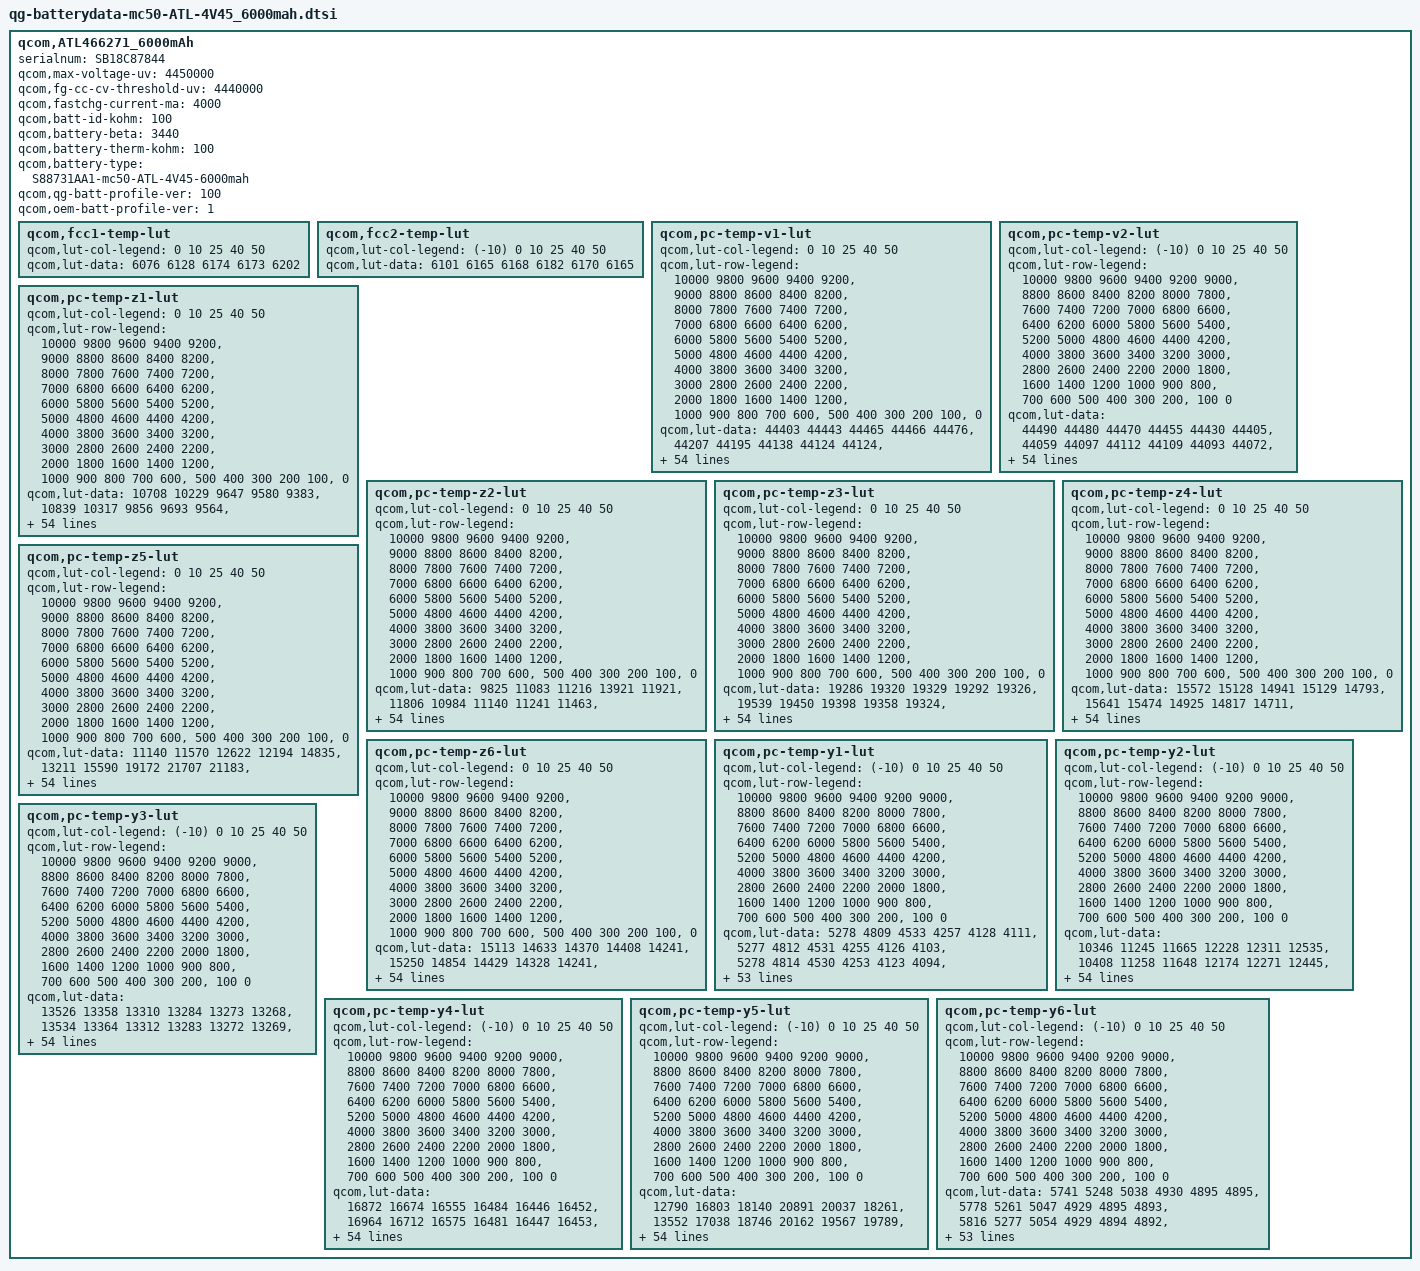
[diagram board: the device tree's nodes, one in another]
qcom,ATL466271_6000mAh {
	/* ATL466271_6000mAh_averaged_MasterSlave_Aug7th2020 */
        serialnum = "SB18C87844";
	qcom,max-voltage-uv = <4450000>;
	qcom,fg-cc-cv-threshold-uv = <4440000>;
	qcom,fastchg-current-ma = <4000>;
	qcom,batt-id-kohm = <100>;
	qcom,battery-beta = <3440>;
	qcom,battery-therm-kohm = <100>; /* on sub-board 100K */
	qcom,battery-type = "S88731AA1-mc50-ATL-4V45-6000mah";
	qcom,qg-batt-profile-ver = <100>;
        qcom,oem-batt-profile-ver = <1>;

	/*qcom,step-chg-ranges = <3500000  4000000  8000000
				4000001  4200000  6000000
				4200001  4400000  4000000>;
	qcom,ocv-based-step-chg;*/

	qcom,fcc1-temp-lut {
		qcom,lut-col-legend = <0 10 25 40 50>;
		qcom,lut-data = <6076 6128 6174 6173 6202>;
	};

	qcom,fcc2-temp-lut {
		qcom,lut-col-legend = <(-10) 0 10 25 40 50>;
		qcom,lut-data = <6101 6165 6168 6182 6170 6165>;
	};

	qcom,pc-temp-v1-lut {
		qcom,lut-col-legend = <0 10 25 40 50>;
		qcom,lut-row-legend = <10000 9800 9600 9400 9200>,
			<9000 8800 8600 8400 8200>,
			<8000 7800 7600 7400 7200>,
			<7000 6800 6600 6400 6200>,
			<6000 5800 5600 5400 5200>,
			<5000 4800 4600 4400 4200>,
			<4000 3800 3600 3400 3200>,
			<3000 2800 2600 2400 2200>,
			<2000 1800 1600 1400 1200>,
			<1000 900 800 700 600>,
			<500 400 300 200 100>,
			<0>;
		qcom,lut-data = <44403 44443 44465 44466 44476>,
			<44207 44195 44138 44124 44124>,
			<43961 43947 43889 43906 43859>,
			<43706 43716 43668 43683 43637>,
			<43464 43481 43444 43456 43420>,
			<43222 43244 43209 43224 43190>,
			<42977 43004 42970 42987 42956>,
			<42728 42756 42726 42745 42718>,
			<42478 42504 42477 42497 42476>,
			<42231 42258 42230 42251 42234>,
			<41986 42014 41986 42008 41993>,
			<41748 41775 41746 41768 41754>,
			<41517 41542 41511 41532 41520>,
			<41292 41313 41279 41298 41288>,
			<41075 41095 41056 41072 41064>,
			<40864 40885 40840 40852 40846>,
			<40655 40679 40633 40643 40636>,
			<40445 40472 40434 40449 40434>,
			<40250 40276 40245 40265 40242>,
			<40073 40105 40072 40089 40061>,
			<39907 39948 39915 39926 39897>,
			<39750 39775 39731 39740 39718>,
			<39603 39585 39458 39491 39482>,
			<39439 39381 39186 39240 39233>,
			<39226 39134 39019 39062 39050>,
			<39010 38883 38898 38918 38905>,
			<38843 38750 38789 38789 38778>,
			<38699 38679 38689 38670 38664>,
			<38599 38617 38596 38563 38560>,
			<38535 38547 38506 38471 38459>,
			<38485 38481 38422 38389 38363>,
			<38437 38415 38349 38315 38278>,
			<38394 38353 38284 38248 38202>,
			<38353 38296 38226 38185 38133>,
			<38312 38247 38179 38127 38075>,
			<38273 38202 38136 38073 38021>,
			<38238 38162 38091 38019 37960>,
			<38204 38127 38048 37968 37896>,
			<38155 38079 37993 37905 37822>,
			<38077 37995 37911 37816 37735>,
			<37976 37889 37808 37714 37633>,
			<37859 37774 37693 37618 37515>,
			<37716 37637 37559 37514 37378>,
			<37541 37469 37397 37353 37246>,
			<37374 37294 37232 37162 37115>,
			<37241 37166 37111 37043 36978>,
			<37204 37126 37082 37018 36967>,
			<37166 37098 37059 36985 36935>,
			<37132 37079 37040 36970 36911>,
			<37097 37047 37009 36938 36866>,
			<36970 36897 36822 36732 36622>,
			<36569 36486 36406 36316 36186>,
			<35983 35903 35832 35755 35657>,
			<35173 35096 35048 35001 34835>,
			<33799 33762 33835 33744 33618>,
			<30000 30000 30000 30000 30000>;
	};

	qcom,pc-temp-v2-lut {
		qcom,lut-col-legend = <(-10) 0 10 25 40 50>;
		qcom,lut-row-legend = <10000 9800 9600 9400 9200 9000>,
			<8800 8600 8400 8200 8000 7800>,
			<7600 7400 7200 7000 6800 6600>,
			<6400 6200 6000 5800 5600 5400>,
			<5200 5000 4800 4600 4400 4200>,
			<4000 3800 3600 3400 3200 3000>,
			<2800 2600 2400 2200 2000 1800>,
			<1600 1400 1200 1000 900 800>,
			<700 600 500 400 300 200>,
			<100 0>;
		qcom,lut-data = <44490 44480 44470 44455 44430 44405>,
			<44059 44097 44112 44109 44093 44072>,
			<43685 43762 43798 43802 43792 43771>,
			<43382 43487 43534 43541 43534 43512>,
			<43138 43260 43315 43321 43315 43289>,
			<42893 43030 43091 43097 43092 43062>,
			<42622 42783 42849 42856 42854 42818>,
			<42352 42532 42602 42612 42612 42571>,
			<42104 42278 42355 42367 42369 42327>,
			<41872 42022 42107 42121 42124 42083>,
			<41639 41777 41864 41877 41883 41843>,
			<41395 41542 41624 41636 41644 41605>,
			<41159 41316 41389 41401 41410 41372>,
			<40955 41097 41159 41171 41183 41144>,
			<40771 40884 40935 40948 40963 40922>,
			<40541 40673 40720 40731 40750 40707>,
			<40203 40468 40513 40521 40543 40498>,
			<39855 40251 40312 40318 40342 40298>,
			<39587 40004 40125 40129 40149 40111>,
			<39354 39743 39938 39944 39957 39931>,
			<39127 39497 39712 39745 39758 39748>,
			<38902 39258 39441 39534 39551 39567>,
			<38703 39041 39197 39320 39342 39371>,
			<38534 38849 38995 39088 39115 39133>,
			<38388 38676 38817 38874 38902 38902>,
			<38286 38523 38665 38720 38749 38744>,
			<38215 38385 38533 38596 38625 38621>,
			<38154 38261 38413 38483 38512 38511>,
			<38098 38142 38302 38377 38401 38407>,
			<38047 38044 38200 38280 38303 38310>,
			<37993 37981 38105 38192 38224 38222>,
			<37938 37934 38018 38112 38154 38140>,
			<37883 37890 37944 38039 38082 38066>,
			<37827 37850 37878 37972 38002 38003>,
			<37771 37808 37824 37906 37927 37934>,
			<37711 37760 37784 37836 37863 37836>,
			<37647 37706 37748 37764 37798 37721>,
			<37578 37646 37701 37686 37718 37613>,
			<37505 37579 37639 37603 37620 37509>,
			<37425 37501 37566 37521 37520 37411>,
			<37337 37398 37474 37446 37424 37328>,
			<37237 37279 37363 37356 37318 37236>,
			<37122 37147 37225 37231 37191 37110>,
			<37003 36987 37075 37102 37067 36978>,
			<36901 36830 36901 36935 36903 36835>,
			<36812 36722 36816 36890 36860 36802>,
			<36769 36681 36780 36873 36851 36789>,
			<36728 36642 36750 36853 36870 36770>,
			<36686 36592 36694 36824 36818 36741>,
			<36634 36504 36602 36751 36729 36647>,
			<36528 36300 36369 36488 36455 36338>,
			<36286 35864 35889 36000 35960 35833>,
			<35817 35150 35212 35350 35298 35166>,
			<35058 34089 34305 34448 34424 34230>,
			<33775 32410 32840 33043 33144 32821>,
			<32320 28352 28072 28339 28428 29837>;
	};

	qcom,pc-temp-z1-lut {
		qcom,lut-col-legend = <0 10 25 40 50>;
		qcom,lut-row-legend = <10000 9800 9600 9400 9200>,
			<9000 8800 8600 8400 8200>,
			<8000 7800 7600 7400 7200>,
			<7000 6800 6600 6400 6200>,
			<6000 5800 5600 5400 5200>,
			<5000 4800 4600 4400 4200>,
			<4000 3800 3600 3400 3200>,
			<3000 2800 2600 2400 2200>,
			<2000 1800 1600 1400 1200>,
			<1000 900 800 700 600>,
			<500 400 300 200 100>,
			<0>;
		qcom,lut-data = <10708 10229 9647 9580 9383>,
			<10839 10317 9856 9693 9564>,
			<10850 10320 9850 9738 9541>,
			<10856 10326 9844 9730 9540>,
			<10864 10326 9838 9720 9539>,
			<10877 10320 9831 9703 9538>,
			<10875 10312 9824 9689 9537>,
			<10846 10300 9818 9691 9538>,
			<10821 10285 9812 9701 9545>,
			<10818 10276 9809 9702 9547>,
			<10819 10269 9806 9666 9541>,
			<10816 10264 9804 9635 9534>,
			<10805 10260 9802 9653 9538>,
			<10795 10257 9800 9691 9553>,
			<10789 10256 9799 9695 9557>,
			<10782 10256 9797 9662 9544>,
			<10776 10255 9796 9639 9534>,
			<10770 10248 9798 9638 9537>,
			<10766 10241 9801 9637 9544>,
			<10768 10246 9801 9638 9550>,
			<10770 10257 9799 9638 9557>,
			<10770 10262 9798 9639 9560>,
			<10767 10264 9799 9662 9552>,
			<10767 10265 9801 9687 9542>,
			<10775 10265 9803 9680 9542>,
			<10786 10265 9807 9656 9546>,
			<10784 10266 9811 9648 9548>,
			<10771 10272 9815 9654 9549>,
			<10766 10276 9819 9662 9549>,
			<10775 10275 9823 9669 9550>,
			<10787 10271 9826 9675 9552>,
			<10796 10271 9828 9678 9557>,
			<10804 10273 9830 9679 9575>,
			<10807 10276 9833 9681 9588>,
			<10806 10282 9836 9683 9583>,
			<10806 10291 9840 9684 9574>,
			<10819 10298 9843 9685 9575>,
			<10846 10306 9845 9686 9584>,
			<10854 10309 9847 9687 9589>,
			<10845 10307 9851 9693 9587>,
			<10837 10306 9855 9702 9584>,
			<10845 10320 9862 9709 9590>,
			<10865 10342 9870 9717 9604>,
			<10887 10342 9873 9742 9596>,
			<10908 10346 9878 9749 9583>,
			<10904 10348 9882 9737 9594>,
			<10898 10362 9884 9738 9586>,
			<10904 10366 9886 9730 9574>,
			<10906 10354 9882 9741 9575>,
			<10885 10364 9887 9738 9577>,
			<10915 10372 9895 9751 9580>,
			<10908 10384 9906 9765 9624>,
			<10963 10405 9909 9725 9601>,
			<11011 10440 9926 9751 9592>,
			<11011 10440 9926 9751 9592>,
			<11011 10440 9926 9751 9592>;
	};

	qcom,pc-temp-z2-lut {
		qcom,lut-col-legend = <0 10 25 40 50>;
		qcom,lut-row-legend = <10000 9800 9600 9400 9200>,
			<9000 8800 8600 8400 8200>,
			<8000 7800 7600 7400 7200>,
			<7000 6800 6600 6400 6200>,
			<6000 5800 5600 5400 5200>,
			<5000 4800 4600 4400 4200>,
			<4000 3800 3600 3400 3200>,
			<3000 2800 2600 2400 2200>,
			<2000 1800 1600 1400 1200>,
			<1000 900 800 700 600>,
			<500 400 300 200 100>,
			<0>;
		qcom,lut-data = <9825 11083 11216 13921 11921>,
			<11806 10984 11140 11241 11463>,
			<11214 10949 11207 11503 11629>,
			<10684 10840 11132 11435 11585>,
			<10624 10788 11066 11386 11550>,
			<10596 10733 11020 11374 11574>,
			<10590 10683 10988 11374 11614>,
			<10593 10644 11001 11389 11610>,
			<10593 10614 11045 11419 11554>,
			<10574 10622 11077 11426 11506>,
			<10542 10673 11099 11379 11497>,
			<10536 10713 11118 11337 11508>,
			<10540 10729 11135 11360 11513>,
			<10548 10743 11150 11414 11501>,
			<10573 10767 11170 11438 11491>,
			<10607 10799 11198 11464 11498>,
			<10618 10827 11223 11478 11507>,
			<10620 10851 11241 11453 11522>,
			<10624 10873 11256 11415 11547>,
			<10643 10896 11273 11406 11552>,
			<10673 10921 11294 11407 11569>,
			<10697 10941 11321 11430 11618>,
			<10721 10961 11385 11480 11931>,
			<10739 10973 11446 11539 12346>,
			<10751 10974 11411 11632 12383>,
			<10760 10973 11287 11775 12253>,
			<10771 10972 11246 11814 12119>,
			<10783 10968 11351 11700 11878>,
			<10795 10967 11449 11561 11649>,
			<10809 10983 11416 11460 11588>,
			<10823 11006 11334 11358 11552>,
			<10835 11013 11295 11338 11536>,
			<10846 11014 11273 11359 11529>,
			<10856 11015 11263 11392 11536>,
			<10863 11018 11293 11465 11557>,
			<10870 11022 11349 11556 11588>,
			<10878 11026 11383 11589 11656>,
			<10887 11030 11408 11595 11821>,
			<10900 11039 11432 11597 11911>,
			<10919 11066 11466 11598 11903>,
			<10943 11095 11496 11599 11894>,
			<10966 11106 11501 11684 11935>,
			<10997 11115 11496 11868 12059>,
			<11062 11134 11499 11881 11996>,
			<11187 11262 11550 11776 12022>,
			<11338 11556 11646 11627 12000>,
			<11040 11551 11653 11644 12454>,
			<10950 11673 11585 11576 12004>,
			<10958 12095 11610 11558 11921>,
			<10509 12218 11649 11614 12049>,
			<10765 12168 11877 11644 11613>,
			<10420 12160 12029 11864 11419>,
			<10349 11922 11952 13651 11585>,
			<10177 11499 11848 13870 11361>,
			<10177 11499 11848 13870 11361>,
			<10177 11499 11848 13870 11361>;
	};

	qcom,pc-temp-z3-lut {
		qcom,lut-col-legend = <0 10 25 40 50>;
		qcom,lut-row-legend = <10000 9800 9600 9400 9200>,
			<9000 8800 8600 8400 8200>,
			<8000 7800 7600 7400 7200>,
			<7000 6800 6600 6400 6200>,
			<6000 5800 5600 5400 5200>,
			<5000 4800 4600 4400 4200>,
			<4000 3800 3600 3400 3200>,
			<3000 2800 2600 2400 2200>,
			<2000 1800 1600 1400 1200>,
			<1000 900 800 700 600>,
			<500 400 300 200 100>,
			<0>;
		qcom,lut-data = <19286 19320 19329 19292 19326>,
			<19539 19450 19398 19358 19324>,
			<19620 19495 19432 19353 19349>,
			<19669 19551 19443 19360 19350>,
			<19703 19570 19447 19363 19350>,
			<19727 19577 19445 19361 19349>,
			<19730 19580 19440 19357 19347>,
			<19721 19582 19434 19358 19346>,
			<19713 19582 19424 19361 19345>,
			<19715 19576 19415 19361 19343>,
			<19719 19555 19408 19355 19336>,
			<19719 19539 19402 19350 19327>,
			<19714 19531 19399 19351 19327>,
			<19706 19525 19397 19355 19327>,
			<19696 19518 19394 19355 19327>,
			<19685 19510 19391 19350 19320>,
			<19680 19506 19389 19343 19315>,
			<19677 19501 19386 19335 19316>,
			<19673 19498 19384 19326 19317>,
			<19660 19496 19381 19324 19317>,
			<19645 19492 19377 19324 19314>,
			<19640 19492 19375 19324 19313>,
			<19638 19496 19387 19340 19318>,
			<19639 19500 19401 19356 19327>,
			<19649 19503 19395 19352 19328>,
			<19660 19507 19373 19336 19322>,
			<19660 19506 19366 19332 19319>,
			<19656 19496 19373 19355 19325>,
			<19652 19489 19382 19376 19333>,
			<19646 19490 19392 19373 19333>,
			<19639 19490 19404 19364 19332>,
			<19634 19492 19406 19358 19332>,
			<19628 19496 19402 19353 19331>,
			<19625 19498 19397 19349 19330>,
			<19622 19497 19392 19346 19324>,
			<19620 19495 19387 19345 19316>,
			<19617 19493 19384 19343 19315>,
			<19612 19489 19382 19342 19316>,
			<19608 19486 19380 19341 19317>,
			<19602 19481 19378 19340 19317>,
			<19596 19477 19376 19339 19317>,
			<19585 19472 19374 19332 19319>,
			<19571 19467 19373 19317 19323>,
			<19556 19458 19369 19314 19313>,
			<19477 19437 19361 19318 19297>,
			<19377 19401 19351 19318 19302>,
			<19308 19398 19347 19318 19290>,
			<19302 19382 19347 19320 19295>,
			<19295 19302 19342 19314 19295>,
			<19280 19289 19335 19311 19297>,
			<19288 19322 19325 19310 19308>,
			<19278 19296 19307 19301 19324>,
			<19299 19300 19309 19292 19299>,
			<19312 19305 19315 19293 19310>,
			<19312 19305 19315 19293 19310>,
			<19312 19305 19315 19293 19310>;
	};

	qcom,pc-temp-z4-lut {
		qcom,lut-col-legend = <0 10 25 40 50>;
		qcom,lut-row-legend = <10000 9800 9600 9400 9200>,
			<9000 8800 8600 8400 8200>,
			<8000 7800 7600 7400 7200>,
			<7000 6800 6600 6400 6200>,
			<6000 5800 5600 5400 5200>,
			<5000 4800 4600 4400 4200>,
			<4000 3800 3600 3400 3200>,
			<3000 2800 2600 2400 2200>,
			<2000 1800 1600 1400 1200>,
			<1000 900 800 700 600>,
			<500 400 300 200 100>,
			<0>;
		qcom,lut-data = <15572 15128 14941 15129 14793>,
			<15641 15474 14925 14817 14711>,
			<15716 15422 15016 14923 14752>,
			<15762 15236 14915 14870 14721>,
			<15654 15105 14830 14818 14692>,
			<15437 15005 14783 14777 14684>,
			<15285 14928 14750 14744 14680>,
			<15182 14872 14735 14733 14678>,
			<15098 14828 14725 14727 14679>,
			<15028 14795 14718 14719 14678>,
			<14968 14769 14713 14702 14673>,
			<14917 14753 14708 14689 14667>,
			<14874 14744 14702 14690 14666>,
			<14837 14739 14695 14694 14665>,
			<14802 14733 14689 14691 14663>,
			<14774 14727 14684 14671 14657>,
			<14764 14723 14680 14658 14649>,
			<14759 14723 14676 14659 14644>,
			<14757 14722 14672 14659 14639>,
			<14758 14715 14669 14658 14637>,
			<14760 14702 14667 14655 14637>,
			<14756 14698 14667 14655 14639>,
			<14739 14705 14699 14685 14658>,
			<14730 14718 14744 14723 14686>,
			<14748 14755 14765 14734 14698>,
			<14778 14809 14780 14741 14705>,
			<14800 14819 14783 14740 14707>,
			<14821 14808 14765 14708 14689>,
			<14828 14793 14742 14677 14666>,
			<14821 14779 14721 14674 14657>,
			<14809 14764 14700 14673 14650>,
			<14798 14751 14692 14672 14648>,
			<14787 14738 14689 14669 14649>,
			<14776 14730 14688 14668 14650>,
			<14766 14725 14687 14667 14650>,
			<14756 14721 14686 14668 14649>,
			<14747 14717 14686 14669 14651>,
			<14737 14713 14687 14673 14663>,
			<14730 14711 14688 14677 14669>,
			<14723 14711 14690 14682 14665>,
			<14718 14711 14693 14688 14660>,
			<14713 14705 14689 14689 14661>,
			<14708 14691 14677 14689 14664>,
			<14697 14684 14671 14694 14662>,
			<14719 14672 14661 14687 14653>,
			<14772 14664 14648 14666 14647>,
			<14844 14663 14644 14659 14644>,
			<14848 14672 14635 14648 14627>,
			<14851 14758 14630 14646 14616>,
			<14860 14765 14633 14643 14613>,
			<14847 14731 14656 14663 14617>,
			<14870 14768 14681 14679 14633>,
			<14860 14770 14679 14665 14624>,
			<14866 14773 14675 14657 14620>,
			<14866 14773 14675 14657 14620>,
			<14866 14773 14675 14657 14620>;
	};

	qcom,pc-temp-z5-lut {
		qcom,lut-col-legend = <0 10 25 40 50>;
		qcom,lut-row-legend = <10000 9800 9600 9400 9200>,
			<9000 8800 8600 8400 8200>,
			<8000 7800 7600 7400 7200>,
			<7000 6800 6600 6400 6200>,
			<6000 5800 5600 5400 5200>,
			<5000 4800 4600 4400 4200>,
			<4000 3800 3600 3400 3200>,
			<3000 2800 2600 2400 2200>,
			<2000 1800 1600 1400 1200>,
			<1000 900 800 700 600>,
			<500 400 300 200 100>,
			<0>;
		qcom,lut-data = <11140 11570 12622 12194 14835>,
			<13211 15590 19172 21707 21183>,
			<14425 15533 18678 17683 23043>,
			<15251 17215 20011 18761 24939>,
			<15887 18421 21410 19438 26507>,
			<16392 19285 22696 20026 27263>,
			<16864 20214 23721 20637 27776>,
			<17322 21489 24048 20903 27675>,
			<17834 22875 24179 21379 26644>,
			<18585 24056 24133 21600 25685>,
			<19619 25149 23973 21760 25147>,
			<20723 25958 23849 21848 24957>,
			<21930 26637 24196 22062 25339>,
			<23403 27127 25135 22588 25934>,
			<25620 27427 26019 23283 25948>,
			<28194 28023 26859 26556 25809>,
			<30330 28372 27768 28660 25909>,
			<32395 29691 28965 26570 28588>,
			<33283 30915 30263 23544 33478>,
			<31977 31327 31053 23193 34181>,
			<30157 32643 31717 23746 31511>,
			<30624 35054 33004 24740 30665>,
			<34427 42825 43943 29332 35941>,
			<39743 48777 56195 34073 42709>,
			<52852 49207 50724 31619 40441>,
			<65535 49140 31430 23448 26676>,
			<65535 47375 23864 20977 19864>,
			<61512 39006 23963 28594 21979>,
			<57109 33572 24595 35950 25007>,
			<52662 33637 27865 36181 27649>,
			<48821 33848 34423 34754 31558>,
			<46667 35005 38811 34530 34021>,
			<45097 39367 41938 35856 35705>,
			<44713 43466 43755 37643 36741>,
			<45530 46675 44421 41555 36954>,
			<46437 49082 44759 46148 36788>,
			<46768 49579 44614 46551 36128>,
			<47176 49175 44232 45155 34346>,
			<47879 48690 43559 43881 33460>,
			<50055 47864 40548 41648 36740>,
			<51749 46639 37429 38000 40549>,
			<48642 44975 37328 31529 38972>,
			<43305 42659 37677 23579 33171>,
			<43137 39303 35715 23720 25952>,
			<34797 37962 34411 28737 21728>,
			<21074 32012 35350 29274 23908>,
			<13843 29691 32903 28774 20866>,
			<13296 24496 34496 37721 26313>,
			<13048 14276 33055 33163 33103>,
			<12666 13340 28801 33205 34583>,
			<12947 15826 21358 24463 34247>,
			<12623 13660 16311 21348 35544>,
			<12872 13517 16200 20604 22641>,
			<12930 13512 16441 21168 28792>,
			<12930 13512 16441 21168 28792>,
			<12930 13512 16441 21168 28792>;
	};

	qcom,pc-temp-z6-lut {
		qcom,lut-col-legend = <0 10 25 40 50>;
		qcom,lut-row-legend = <10000 9800 9600 9400 9200>,
			<9000 8800 8600 8400 8200>,
			<8000 7800 7600 7400 7200>,
			<7000 6800 6600 6400 6200>,
			<6000 5800 5600 5400 5200>,
			<5000 4800 4600 4400 4200>,
			<4000 3800 3600 3400 3200>,
			<3000 2800 2600 2400 2200>,
			<2000 1800 1600 1400 1200>,
			<1000 900 800 700 600>,
			<500 400 300 200 100>,
			<0>;
		qcom,lut-data = <15113 14633 14370 14408 14241>,
			<15250 14854 14429 14328 14241>,
			<15291 14839 14481 14379 14267>,
			<15306 14781 14443 14359 14255>,
			<15264 14730 14408 14337 14243>,
			<15162 14680 14385 14313 14238>,
			<15080 14639 14367 14295 14235>,
			<15014 14610 14355 14292 14234>,
			<14960 14587 14345 14292 14235>,
			<14921 14562 14337 14289 14234>,
			<14890 14536 14330 14272 14227>,
			<14859 14519 14324 14257 14219>,
			<14829 14510 14319 14261 14218>,
			<14801 14504 14314 14272 14221>,
			<14777 14497 14310 14271 14220>,
			<14756 14490 14306 14254 14211>,
			<14747 14485 14303 14240 14203>,
			<14742 14482 14300 14235 14202>,
			<14738 14479 14297 14231 14201>,
			<14734 14474 14294 14229 14201>,
			<14731 14467 14291 14228 14201>,
			<14726 14466 14290 14228 14202>,
			<14716 14471 14313 14254 14212>,
			<14713 14480 14339 14284 14227>,
			<14728 14500 14341 14284 14231>,
			<14749 14526 14339 14275 14233>,
			<14761 14530 14337 14271 14233>,
			<14771 14522 14334 14270 14228>,
			<14773 14513 14330 14269 14223>,
			<14767 14506 14328 14267 14220>,
			<14758 14501 14325 14264 14217>,
			<14751 14498 14323 14261 14215>,
			<14746 14496 14320 14257 14219>,
			<14741 14494 14317 14254 14221>,
			<14737 14492 14315 14253 14216>,
			<14734 14490 14312 14252 14210>,
			<14732 14490 14311 14252 14210>,
			<14731 14489 14311 14253 14217>,
			<14730 14488 14311 14254 14221>,
			<14730 14489 14312 14257 14218>,
			<14729 14489 14313 14260 14215>,
			<14727 14487 14312 14258 14218>,
			<14724 14484 14307 14252 14224>,
			<14720 14481 14304 14258 14217>,
			<14701 14472 14297 14258 14203>,
			<14678 14454 14288 14246 14204>,
			<14678 14453 14284 14243 14195>,
			<14677 14450 14281 14238 14188>,
			<14676 14448 14276 14236 14183>,
			<14674 14447 14275 14233 14183>,
			<14681 14452 14282 14244 14191>,
			<14694 14460 14286 14250 14215>,
			<14711 14470 14288 14231 14194>,
			<14740 14484 14292 14234 14197>,
			<14740 14484 14292 14234 14197>,
			<14740 14484 14292 14234 14197>;
	};

	qcom,pc-temp-y1-lut {
		qcom,lut-col-legend = <(-10) 0 10 25 40 50>;
		qcom,lut-row-legend = <10000 9800 9600 9400 9200 9000>,
			<8800 8600 8400 8200 8000 7800>,
			<7600 7400 7200 7000 6800 6600>,
			<6400 6200 6000 5800 5600 5400>,
			<5200 5000 4800 4600 4400 4200>,
			<4000 3800 3600 3400 3200 3000>,
			<2800 2600 2400 2200 2000 1800>,
			<1600 1400 1200 1000 900 800>,
			<700 600 500 400 300 200>,
			<100 0>;
		qcom,lut-data = <5278 4809 4533 4257 4128 4111>,
			<5277 4812 4531 4255 4126 4103>,
			<5278 4814 4530 4253 4123 4094>,
			<5280 4815 4528 4250 4121 4085>,
			<5282 4815 4527 4248 4119 4077>,
			<5284 4816 4525 4245 4118 4072>,
			<5293 4815 4524 4241 4117 4070>,
			<5303 4814 4522 4238 4116 4068>,
			<5303 4817 4522 4237 4116 4067>,
			<5299 4826 4523 4237 4115 4064>,
			<5297 4829 4523 4237 4114 4064>,
			<5308 4821 4526 4234 4112 4065>,
			<5321 4815 4527 4231 4110 4065>,
			<5319 4817 4521 4231 4113 4065>,
			<5309 4822 4508 4230 4123 4064>,
			<5305 4823 4506 4229 4142 4064>,
			<5306 4822 4511 4227 4187 4063>,
			<5307 4820 4514 4226 4216 4063>,
			<5308 4820 4512 4226 4194 4064>,
			<5308 4819 4508 4227 4161 4066>,
			<5308 4819 4509 4229 4156 4066>,
			<5307 4819 4517 4231 4156 4066>,
			<5306 4820 4522 4232 4156 4066>,
			<5308 4822 4524 4232 4163 4067>,
			<5311 4824 4525 4232 4171 4069>,
			<5316 4828 4524 4232 4166 4069>,
			<5332 4833 4521 4232 4148 4069>,
			<5342 4837 4520 4233 4142 4069>,
			<5331 4842 4522 4236 4153 4070>,
			<5311 4845 4525 4240 4163 4070>,
			<5306 4847 4529 4242 4164 4071>,
			<5306 4852 4535 4245 4164 4072>,
			<5306 4853 4537 4247 4164 4073>,
			<5314 4849 4535 4249 4159 4074>,
			<5325 4846 4533 4251 4156 4075>,
			<5332 4846 4535 4254 4158 4076>,
			<5347 4847 4537 4257 4160 4078>,
			<5354 4850 4540 4258 4160 4078>,
			<5339 4859 4547 4259 4156 4079>,
			<5321 4865 4550 4260 4154 4079>,
			<5321 4861 4551 4265 4155 4080>,
			<5328 4857 4553 4267 4159 4081>,
			<5345 4855 4554 4269 4187 4082>,
			<5353 4867 4573 4272 4174 4082>,
			<5336 4860 4569 4272 4201 4082>,
			<5350 4872 4578 4278 4199 4084>,
			<5351 4871 4581 4280 4186 4085>,
			<5347 4877 4578 4278 4164 4085>,
			<5376 4889 4575 4280 4174 4086>,
			<5395 4890 4584 4284 4194 4086>,
			<5421 4896 4580 4283 4210 4086>,
			<5504 4940 4592 4288 4203 4089>,
			<5511 5014 4611 4300 4207 4092>,
			<5635 5122 4657 4314 4193 4094>,
			<5635 5122 4657 4314 4193 4094>,
			<5635 5122 4657 4314 4193 4094>;
	};

	qcom,pc-temp-y2-lut {
		qcom,lut-col-legend = <(-10) 0 10 25 40 50>;
		qcom,lut-row-legend = <10000 9800 9600 9400 9200 9000>,
			<8800 8600 8400 8200 8000 7800>,
			<7600 7400 7200 7000 6800 6600>,
			<6400 6200 6000 5800 5600 5400>,
			<5200 5000 4800 4600 4400 4200>,
			<4000 3800 3600 3400 3200 3000>,
			<2800 2600 2400 2200 2000 1800>,
			<1600 1400 1200 1000 900 800>,
			<700 600 500 400 300 200>,
			<100 0>;
		qcom,lut-data = <10346 11245 11665 12228 12311 12535>,
			<10408 11258 11648 12174 12271 12445>,
			<10495 11261 11625 12080 12227 12351>,
			<10585 11257 11598 11977 12180 12263>,
			<10661 11249 11568 11894 12135 12189>,
			<10703 11237 11537 11861 12095 12140>,
			<10725 11213 11482 11857 12051 12104>,
			<10741 11186 11428 11854 12013 12082>,
			<10753 11167 11408 11840 11987 12066>,
			<10789 11148 11396 11815 11961 12025>,
			<10806 11143 11383 11808 11956 12014>,
			<10860 11148 11364 11823 11990 12038>,
			<10923 11158 11350 11830 12018 12068>,
			<10913 11223 11359 11796 11989 12079>,
			<10865 11343 11387 11745 11924 12080>,
			<10828 11369 11428 11743 11857 12089>,
			<10619 11330 11506 11802 11767 12125>,
			<10427 11302 11577 11864 11716 12152>,
			<10257 11337 11626 11920 11820 12163>,
			<9855 11396 11662 11968 11998 12181>,
			<9704 11411 11661 11968 12087 12222>,
			<9691 11396 11639 11948 12198 12316>,
			<9684 11392 11628 11940 12258 12386>,
			<9679 11425 11657 11986 12261 12448>,
			<9676 11464 11703 12052 12256 12502>,
			<9673 11472 11735 12098 12249 12489>,
			<9671 11470 11767 12139 12244 12430>,
			<9669 11478 11797 12159 12283 12411>,
			<9668 11523 11829 12172 12428 12486>,
			<9666 11561 11853 12188 12568 12566>,
			<9664 11539 11865 12224 12616 12576>,
			<9663 11456 11875 12269 12646 12573>,
			<9662 11303 11877 12274 12699 12602>,
			<9661 10871 11879 12247 12906 12747>,
			<9661 10505 11879 12222 13029 12851>,
			<9660 10209 11852 12241 12801 12729>,
			<9660 9835 11789 12274 12430 12521>,
			<9660 9729 11722 12273 12275 12540>,
			<9660 9698 11642 12281 12273 12844>,
			<9660 9683 11548 12293 12289 13019>,
			<9659 9675 11429 12240 12378 12777>,
			<9659 9670 11294 12161 12439 12521>,
			<9659 9667 11139 12016 12121 12443>,
			<9659 9664 10961 12094 12262 12508>,
			<9658 9663 10885 12239 11880 12365>,
			<9658 9660 10632 11967 11734 12261>,
			<9658 9659 10370 11982 13156 12314>,
			<9657 9658 10246 12059 12929 12277>,
			<9656 9657 9949 11921 11628 12269>,
			<9654 9656 9752 11802 13623 12170>,
			<9653 9655 9697 11789 12706 12025>,
			<9651 9652 9673 11692 11735 11998>,
			<9650 9651 9661 11541 11854 11982>,
			<9650 9651 9654 11415 13848 11737>,
			<9650 9651 9654 11415 13848 11737>,
			<9650 9651 9654 11415 13848 11737>;
	};

	qcom,pc-temp-y3-lut {
		qcom,lut-col-legend = <(-10) 0 10 25 40 50>;
		qcom,lut-row-legend = <10000 9800 9600 9400 9200 9000>,
			<8800 8600 8400 8200 8000 7800>,
			<7600 7400 7200 7000 6800 6600>,
			<6400 6200 6000 5800 5600 5400>,
			<5200 5000 4800 4600 4400 4200>,
			<4000 3800 3600 3400 3200 3000>,
			<2800 2600 2400 2200 2000 1800>,
			<1600 1400 1200 1000 900 800>,
			<700 600 500 400 300 200>,
			<100 0>;
		qcom,lut-data = <13526 13358 13310 13284 13273 13268>,
			<13534 13364 13312 13283 13272 13269>,
			<13539 13370 13315 13282 13271 13269>,
			<13543 13376 13319 13282 13271 13270>,
			<13545 13380 13321 13281 13270 13270>,
			<13547 13384 13323 13281 13270 13270>,
			<13545 13386 13324 13282 13271 13270>,
			<13544 13387 13325 13282 13272 13269>,
			<13548 13389 13325 13283 13272 13270>,
			<13561 13390 13326 13285 13272 13270>,
			<13565 13391 13326 13285 13272 13270>,
			<13513 13394 13327 13284 13273 13271>,
			<13456 13395 13327 13284 13273 13271>,
			<13456 13391 13327 13285 13274 13271>,
			<13471 13380 13327 13289 13276 13271>,
			<13477 13376 13327 13290 13278 13271>,
			<13470 13376 13326 13290 13281 13270>,
			<13462 13375 13326 13290 13283 13270>,
			<13459 13370 13326 13291 13284 13270>,
			<13457 13361 13327 13292 13284 13272>,
			<13453 13355 13325 13292 13285 13274>,
			<13443 13349 13318 13291 13285 13276>,
			<13435 13344 13312 13290 13284 13277>,
			<13431 13340 13309 13285 13280 13273>,
			<13428 13336 13307 13281 13276 13268>,
			<13432 13334 13306 13281 13275 13268>,
			<13453 13332 13305 13281 13274 13268>,
			<13482 13328 13304 13282 13273 13267>,
			<13516 13315 13303 13280 13271 13267>,
			<13559 13304 13301 13279 13269 13267>,
			<13606 13302 13300 13279 13270 13267>,
			<13659 13303 13298 13280 13273 13267>,
			<13720 13307 13297 13281 13277 13267>,
			<13792 13316 13296 13281 13286 13268>,
			<13872 13326 13295 13282 13291 13269>,
			<13954 13335 13297 13281 13284 13268>,
			<14040 13347 13301 13279 13273 13267>,
			<14123 13364 13303 13277 13271 13267>,
			<14200 13392 13305 13275 13271 13268>,
			<14273 13428 13307 13274 13272 13268>,
			<14338 13472 13310 13275 13281 13268>,
			<14397 13527 13313 13277 13286 13267>,
			<14447 13598 13318 13279 13278 13268>,
			<14498 13693 13323 13280 13283 13268>,
			<14531 13738 13319 13274 13271 13268>,
			<14652 13932 13329 13280 13273 13268>,
			<14747 14075 13335 13280 13282 13269>,
			<14899 14257 13351 13281 13282 13270>,
			<15121 14476 13373 13285 13278 13273>,
			<15580 14727 13418 13290 13293 13273>,
			<17009 15064 13482 13290 13274 13272>,
			<20876 16377 13602 13292 13273 13273>,
			<32537 21960 13975 13297 13275 13273>,
			<65535 46584 15344 13304 13302 13275>,
			<65535 46584 15344 13304 13302 13275>,
			<65535 46584 15344 13304 13302 13275>;
	};

	qcom,pc-temp-y4-lut {
		qcom,lut-col-legend = <(-10) 0 10 25 40 50>;
		qcom,lut-row-legend = <10000 9800 9600 9400 9200 9000>,
			<8800 8600 8400 8200 8000 7800>,
			<7600 7400 7200 7000 6800 6600>,
			<6400 6200 6000 5800 5600 5400>,
			<5200 5000 4800 4600 4400 4200>,
			<4000 3800 3600 3400 3200 3000>,
			<2800 2600 2400 2200 2000 1800>,
			<1600 1400 1200 1000 900 800>,
			<700 600 500 400 300 200>,
			<100 0>;
		qcom,lut-data = <16872 16674 16555 16484 16446 16452>,
			<16964 16712 16575 16481 16447 16453>,
			<17112 16779 16596 16481 16447 16452>,
			<17270 16853 16616 16481 16448 16450>,
			<17394 16911 16630 16482 16448 16447>,
			<17439 16931 16634 16482 16448 16444>,
			<17429 16929 16630 16483 16447 16440>,
			<17414 16925 16625 16484 16447 16436>,
			<17402 16917 16622 16485 16448 16436>,
			<17391 16904 16620 16485 16450 16437>,
			<17390 16899 16620 16488 16453 16439>,
			<17501 16905 16625 16494 16454 16440>,
			<17624 16918 16633 16501 16456 16443>,
			<17625 16958 16643 16504 16462 16445>,
			<17591 17027 16656 16508 16473 16449>,
			<17536 17056 16678 16514 16490 16453>,
			<17354 17062 16720 16526 16527 16459>,
			<17165 17056 16758 16542 16551 16465>,
			<17099 17004 16782 16568 16553 16471>,
			<17059 16915 16798 16594 16554 16477>,
			<17006 16847 16784 16600 16556 16488>,
			<16925 16786 16702 16601 16559 16508>,
			<16854 16736 16631 16598 16552 16517>,
			<16810 16695 16587 16544 16516 16485>,
			<16778 16661 16557 16484 16477 16445>,
			<16772 16631 16543 16473 16467 16441>,
			<16774 16605 16535 16469 16463 16440>,
			<16776 16592 16531 16468 16462 16440>,
			<16781 16582 16529 16472 16463 16442>,
			<16788 16576 16527 16476 16465 16445>,
			<16797 16581 16523 16480 16475 16448>,
			<16808 16595 16518 16484 16493 16452>,
			<16818 16608 16515 16489 16496 16458>,
			<16826 16628 16510 16495 16467 16466>,
			<16833 16650 16507 16499 16444 16471>,
			<16841 16679 16513 16494 16472 16463>,
			<16850 16712 16526 16484 16515 16449>,
			<16858 16734 16538 16475 16518 16443>,
			<16866 16751 16551 16464 16506 16440>,
			<16872 16758 16565 16460 16493 16439>,
			<16870 16757 16580 16463 16450 16440>,
			<16864 16755 16596 16465 16423 16441>,
			<16853 16752 16611 16465 16421 16436>,
			<16844 16738 16625 16470 16421 16437>,
			<16830 16715 16599 16463 16419 16427>,
			<16818 16726 16625 16467 16420 16433>,
			<16836 16745 16650 16478 16425 16438>,
			<16854 16775 16679 16492 16483 16441>,
			<16879 16817 16727 16509 16462 16466>,
			<16918 16879 16797 16529 16446 16476>,
			<17140 16916 16839 16515 16430 16448>,
			<17829 17115 16876 16519 16427 16440>,
			<20857 19624 16986 16549 16434 16446>,
			<48918 55797 17556 16614 16475 16473>,
			<48918 55797 17556 16614 16475 16473>,
			<48918 55797 17556 16614 16475 16473>;
	};

	qcom,pc-temp-y5-lut {
		qcom,lut-col-legend = <(-10) 0 10 25 40 50>;
		qcom,lut-row-legend = <10000 9800 9600 9400 9200 9000>,
			<8800 8600 8400 8200 8000 7800>,
			<7600 7400 7200 7000 6800 6600>,
			<6400 6200 6000 5800 5600 5400>,
			<5200 5000 4800 4600 4400 4200>,
			<4000 3800 3600 3400 3200 3000>,
			<2800 2600 2400 2200 2000 1800>,
			<1600 1400 1200 1000 900 800>,
			<700 600 500 400 300 200>,
			<100 0>;
		qcom,lut-data = <12790 16803 18140 20891 20037 18261>,
			<13552 17038 18746 20162 19567 19789>,
			<14381 17340 19112 19112 18821 20839>,
			<15184 17649 19291 18024 18022 21454>,
			<15868 17906 19333 17185 17394 21679>,
			<16340 18052 19288 16861 17157 21542>,
			<16620 18155 19071 16495 17171 20680>,
			<16872 18211 18746 16121 17194 19669>,
			<17378 18086 18426 16216 17036 19277>,
			<18259 17777 18044 16478 16627 19047>,
			<18575 17600 17622 16359 16355 18762>,
			<16954 17636 17100 15572 16153 18381>,
			<15145 17637 16571 14968 16020 17941>,
			<16116 16950 16067 15249 15900 17431>,
			<19303 15703 15610 15833 15697 16847>,
			<20433 15692 15463 15902 15596 16225>,
			<18888 17969 15466 15440 15231 15450>,
			<17306 19652 15556 15140 15048 15033>,
			<16862 19704 16779 15274 15172 15271>,
			<16371 19706 18737 15597 15330 15872>,
			<15951 19795 19526 16652 16095 16964>,
			<15370 19965 19894 19459 18438 19185>,
			<14669 20044 20175 20724 19595 20283>,
			<13644 20025 20464 20047 18895 19925>,
			<12472 20014 20698 19310 18081 19433>,
			<12168 20101 20847 19682 18261 19405>,
			<12145 20321 21025 20842 18992 19662>,
			<12137 20234 21048 21145 19164 19675>,
			<12205 17231 20523 19990 17562 19068>,
			<12327 14124 20041 19027 16070 18406>,
			<12364 13607 19960 19340 16642 18079>,
			<12327 13434 19696 20147 18548 17814>,
			<12320 13468 19251 20981 22891 17873>,
			<12448 13890 18622 22078 40155 18883>,
			<12617 14198 18266 22616 52231 19746>,
			<12696 13886 18879 22245 41746 19887>,
			<12744 13414 19876 21452 24590 19977>,
			<12796 13498 19942 20141 21532 20534>,
			<12874 13857 19335 17808 21648 22536>,
			<12951 14038 18667 16870 22405 23648>,
			<12978 13892 18010 18007 61011 22209>,
			<12936 13722 17594 19214 65535 20878>,
			<12636 13642 17345 20031 65535 21909>,
			<12176 13356 17065 19739 65535 21076>,
			<11990 12940 16446 16915 65535 24463>,
			<12140 12988 16398 19326 65471 20460>,
			<11993 12828 15552 17933 65535 20077>,
			<11977 12823 15498 17125 55524 21086>,
			<12077 12841 14485 17759 65535 22055>,
			<12181 12934 14259 19011 65535 20731>,
			<11485 12910 14166 19809 65535 24316>,
			<10200 11751 13533 20262 65535 26216>,
			<9308 9765 12748 20712 60775 22703>,
			<8907 8934 11250 20512 31971 23690>,
			<8907 8934 11250 20512 31971 23690>,
			<8907 8934 11250 20512 31971 23690>;
	};

	qcom,pc-temp-y6-lut {
		qcom,lut-col-legend = <(-10) 0 10 25 40 50>;
		qcom,lut-row-legend = <10000 9800 9600 9400 9200 9000>,
			<8800 8600 8400 8200 8000 7800>,
			<7600 7400 7200 7000 6800 6600>,
			<6400 6200 6000 5800 5600 5400>,
			<5200 5000 4800 4600 4400 4200>,
			<4000 3800 3600 3400 3200 3000>,
			<2800 2600 2400 2200 2000 1800>,
			<1600 1400 1200 1000 900 800>,
			<700 600 500 400 300 200>,
			<100 0>;
		qcom,lut-data = <5741 5248 5038 4930 4895 4895>,
			<5778 5261 5047 4929 4895 4893>,
			<5816 5277 5054 4929 4894 4892>,
			<5848 5293 5060 4928 4894 4890>,
			<5870 5305 5064 4928 4894 4889>,
			<5877 5309 5065 4928 4894 4887>,
			<5868 5307 5063 4928 4894 4886>,
			<5856 5304 5060 4928 4894 4885>,
			<5855 5300 5057 4929 4895 4885>,
			<5857 5293 5055 4929 4895 4885>,
			<5859 5291 5055 4930 4896 4885>,
			<5858 5292 5055 4931 4897 4886>,
			<5857 5293 5057 4933 4898 4887>,
			<5857 5299 5058 4935 4900 4888>,
			<5860 5309 5061 4937 4906 4889>,
			<5856 5314 5066 4941 4915 4890>,
			<5798 5317 5077 4944 4933 4891>,
			<5734 5316 5088 4948 4945 4893>,
			<5713 5300 5094 4956 4944 4895>,
			<5700 5270 5099 4964 4940 4898>,
			<5684 5247 5094 4966 4939 4903>,
			<5662 5227 5066 4965 4939 4910>,
			<5648 5211 5043 4963 4937 4913>,
			<5650 5200 5028 4944 4925 4901>,
			<5658 5192 5019 4924 4912 4886>,
			<5670 5190 5015 4922 4907 4884>,
			<5695 5189 5013 4921 4903 4884>,
			<5727 5188 5012 4921 4902 4884>,
			<5764 5185 5012 4921 4902 4884>,
			<5809 5182 5012 4922 4903 4885>,
			<5855 5187 5012 4923 4906 4886>,
			<5904 5203 5013 4926 4914 4887>,
			<5958 5223 5013 4928 4916 4889>,
			<6018 5248 5012 4931 4913 4892>,
			<6082 5279 5012 4932 4911 4894>,
			<6149 5313 5017 4931 4914 4891>,
			<6220 5354 5026 4928 4919 4886>,
			<6287 5400 5036 4924 4918 4885>,
			<6349 5456 5045 4919 4914 4885>,
			<6406 5515 5057 4918 4911 4885>,
			<6457 5573 5072 4920 4905 4885>,
			<6503 5637 5090 4923 4901 4885>,
			<6543 5709 5112 4924 4899 4884>,
			<6581 5793 5140 4927 4900 4884>,
			<6605 5830 5128 4922 4895 4881>,
			<6699 5992 5175 4928 4897 4883>,
			<6781 6112 5207 4931 4901 4886>,
			<6907 6262 5256 4937 4918 4888>,
			<7094 6450 5313 4945 4910 4897>,
			<7475 6668 5402 4955 4917 4900>,
			<8674 6947 5503 4951 4902 4891>,
			<11734 8024 5657 4955 4900 4889>,
			<20652 12742 6031 4970 4903 4892>,
			<59777 39702 7280 4998 4929 4901>,
			<59777 39702 7280 4998 4929 4901>,
			<59777 39702 7280 4998 4929 4901>;
	};

};
